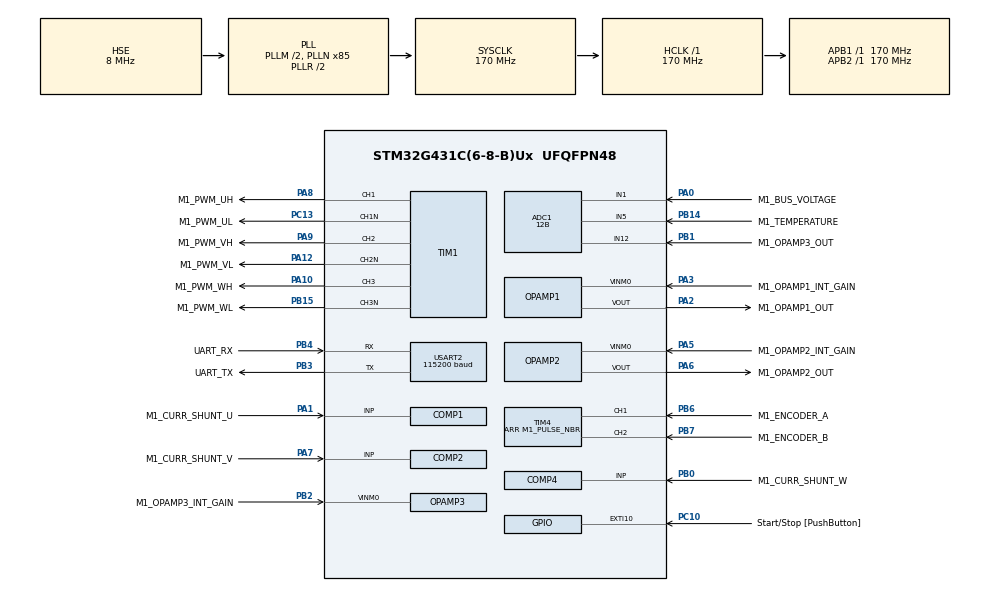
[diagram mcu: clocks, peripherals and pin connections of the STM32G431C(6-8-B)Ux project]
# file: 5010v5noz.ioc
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ADC1.Channel-1\#ChannelRegularConversion=ADC_CHANNEL_1
ADC1.Channel-2\#ChannelRegularConversion=ADC_CHANNEL_5
ADC1.ClockPrescaler=ADC_CLOCK_ASYNC_DIV1
ADC1.ContinuousConvMode=DISABLE
ADC1.DMAContinuousRequests=DISABLE
ADC1.DataAlign=ADC_DATAALIGN_LEFT
ADC1.DiscontinuousConvMode=DISABLE
ADC1.EOCSelection=ADC_EOC_SINGLE_CONV
ADC1.EnableAnalogWatchDog1=false
ADC1.EnableAnalogWatchDog2=false
ADC1.EnableAnalogWatchDog3=false
ADC1.EnableInjectedConversion=ENABLE
ADC1.EnableRegularConversion=ENABLE
ADC1.ExternalTrigConv=ADC_SOFTWARE_START
ADC1.ExternalTrigConvEdge=ADC_EXTERNALTRIGCONVEDGE_NONE
ADC1.ExternalTrigInjecConv=ADC_EXTERNALTRIGINJEC_T1_CC4
ADC1.ExternalTrigInjecConvEdge=ADC_EXTERNALTRIGINJECCONV_EDGE_RISING
ADC1.InjNumberOfConversion=2
ADC1.InjectedChannel-1\#ChannelInjectedConversion=ADC_CHANNEL_3
ADC1.InjectedChannel-2\#ChannelInjectedConversion=ADC_CHANNEL_12
ADC1.InjectedConvMode=None
ADC1.InjectedOffset-1\#ChannelInjectedConversion=0
ADC1.InjectedOffset-2\#ChannelInjectedConversion=0
ADC1.InjectedOffsetNumber-1\#ChannelInjectedConversion=ADC_OFFSET_NONE
ADC1.InjectedOffsetNumber-2\#ChannelInjectedConversion=ADC_OFFSET_NONE
ADC1.InjectedRank-1\#ChannelInjectedConversion=1
ADC1.InjectedRank-2\#ChannelInjectedConversion=2
ADC1.InjectedSamplingTime-1\#ChannelInjectedConversion=ADC_SAMPLETIME_6CYCLES_5
ADC1.InjectedSamplingTime-2\#ChannelInjectedConversion=ADC_SAMPLETIME_6CYCLES_5
ADC1.LowPowerAutoWait=DISABLE
ADC1.NbrOfConversion=2
ADC1.NbrOfConversionFlag=1
ADC1.Offset-1\#ChannelRegularConversion=0
ADC1.Offset-2\#ChannelRegularConversion=0
ADC1.OffsetNumber-1\#ChannelRegularConversion=ADC_OFFSET_NONE
ADC1.OffsetNumber-2\#ChannelRegularConversion=ADC_OFFSET_NONE
ADC1.Overrun=ADC_OVR_DATA_PRESERVED
ADC1.Rank-1\#ChannelRegularConversion=1
ADC1.Rank-2\#ChannelRegularConversion=2
ADC1.Resolution=ADC_RESOLUTION_12B
ADC1.SamplingTime-1\#ChannelRegularConversion=ADC_SAMPLETIME_47CYCLES_5
ADC1.SamplingTime-2\#ChannelRegularConversion=ADC_SAMPLETIME_47CYCLES_5
ADC1.ScanConvMode=ADC_SCAN_ENABLE
ADC1.master=1
ADC2.ClockPrescaler=ADC_CLOCK_ASYNC_DIV1
ADC2.ContinuousConvMode=DISABLE
ADC2.DMAContinuousRequests=DISABLE
ADC2.DataAlign=ADC_DATAALIGN_LEFT
ADC2.DiscontinuousConvMode=DISABLE
ADC2.EOCSelection=ADC_EOC_SINGLE_CONV
ADC2.EnableAnalogWatchDog1=false
ADC2.EnableAnalogWatchDog2=false
ADC2.EnableAnalogWatchDog3=false
ADC2.EnableInjectedConversion=ENABLE
ADC2.EnableRegularConversion=DISABLE
ADC2.ExternalTrigInjecConv=ADC_EXTERNALTRIGINJEC_T1_CC4
ADC2.ExternalTrigInjecConvEdge=ADC_EXTERNALTRIGINJECCONV_EDGE_RISING
ADC2.InjNumberOfConversion=2
ADC2.InjectedChannel-1\#ChannelInjectedConversion=ADC_CHANNEL_VOPAMP3_ADC2
ADC2.InjectedChannel-2\#ChannelInjectedConversion=ADC_CHANNEL_3
ADC2.InjectedConvMode=None
ADC2.InjectedOffset-1\#ChannelInjectedConversion=0
ADC2.InjectedOffset-2\#ChannelInjectedConversion=0
ADC2.InjectedOffsetNumber-1\#ChannelInjectedConversion=ADC_OFFSET_NONE
ADC2.InjectedOffsetNumber-2\#ChannelInjectedConversion=ADC_OFFSET_NONE
ADC2.InjectedRank-1\#ChannelInjectedConversion=1
ADC2.InjectedRank-2\#ChannelInjectedConversion=2
ADC2.InjectedSamplingTime-1\#ChannelInjectedConversion=ADC_SAMPLETIME_6CYCLES_5
ADC2.InjectedSamplingTime-2\#ChannelInjectedConversion=ADC_SAMPLETIME_6CYCLES_5
ADC2.LowPowerAutoWait=DISABLE
ADC2.Overrun=ADC_OVR_DATA_PRESERVED
ADC2.Resolution=ADC_RESOLUTION_12B
ADC2.ScanConvMode=ADC_SCAN_ENABLE
ADC2.master=1
DAC3.DAC_Channel-DAC_OUT2_Int=DAC_CHANNEL_2
Dma.Request0=USART2_RX
Dma.Request1=USART2_TX
Dma.USART2_RX.0.Direction=DMA_PERIPH_TO_MEMORY
Dma.USART2_RX.0.EventEnable=DISABLE
Dma.USART2_RX.0.Instance=DMA1_Channel1
Dma.USART2_RX.0.MemDataAlignment=DMA_MDATAALIGN_BYTE
Dma.USART2_RX.0.MemInc=DMA_MINC_ENABLE
Dma.USART2_RX.0.Mode=DMA_NORMAL
Dma.USART2_RX.0.PeriphDataAlignment=DMA_PDATAALIGN_BYTE
Dma.USART2_RX.0.PeriphInc=DMA_PINC_DISABLE
Dma.USART2_RX.0.Polarity=HAL_DMAMUX_REQ_GEN_RISING
Dma.USART2_RX.0.Priority=DMA_PRIORITY_LOW
Dma.USART2_RX.0.RequestNumber=1
Dma.USART2_RX.0.SignalID=NONE
Dma.USART2_RX.0.SyncEnable=DISABLE
Dma.USART2_RX.0.SyncPolarity=HAL_DMAMUX_SYNC_NO_EVENT
Dma.USART2_RX.0.SyncRequestNumber=1
Dma.USART2_RX.0.SyncSignalID=NONE
Dma.USART2_TX.1.Direction=DMA_MEMORY_TO_PERIPH
Dma.USART2_TX.1.EventEnable=DISABLE
Dma.USART2_TX.1.Instance=DMA1_Channel2
Dma.USART2_TX.1.MemDataAlignment=DMA_MDATAALIGN_BYTE
Dma.USART2_TX.1.MemInc=DMA_MINC_ENABLE
Dma.USART2_TX.1.Mode=DMA_NORMAL
Dma.USART2_TX.1.PeriphDataAlignment=DMA_PDATAALIGN_BYTE
Dma.USART2_TX.1.PeriphInc=DMA_PINC_DISABLE
Dma.USART2_TX.1.Polarity=HAL_DMAMUX_REQ_GEN_RISING
Dma.USART2_TX.1.Priority=DMA_PRIORITY_LOW
Dma.USART2_TX.1.RequestNumber=1
Dma.USART2_TX.1.SignalID=NONE
Dma.USART2_TX.1.SyncEnable=DISABLE
Dma.USART2_TX.1.SyncPolarity=HAL_DMAMUX_SYNC_NO_EVENT
Dma.USART2_TX.1.SyncRequestNumber=1
Dma.USART2_TX.1.SyncSignalID=NONE
ExtraMW=MotorControl
ExtraMW.MotorControl.Config=MotorControl
ExtraMW.MotorControl.Mode=MotorControl
ExtraMW.MotorControl.Root=MCSDK_v6.3.2-Full/MotorControl
ExtraMW.MotorControl.Template=templates
Mcu.Family=STM32G4
Mcu.Name=STM32G431C(6-8-B)Ux
Mcu.Package=UFQFPN48
MotorControl.ADC_1_PERIPH=ADC1
MotorControl.ADC_2_PERIPH=ADC2
MotorControl.ADC_AHBPERIPH=RCC_AHBPeriph_ADC12
MotorControl.ADC_CLOCK_WB_DIV=1
MotorControl.ADC_PERIPH=ADC1
MotorControl.ADC_REFERENCE_VOLTAGE=3.3
MotorControl.BOARD=B-G431B-ESC1
MotorControl.BUS_VOLTAGE_READING=true
MotorControl.CCMRAM_ENABLED=false
MotorControl.CLOCK_FREQUENCY=CPU_CLK_170_MHZ
MotorControl.CLOCK_SOURCE=EXTERNAL
MotorControl.CPU_CLK_170_MHZ=true
MotorControl.CTLBOARD_NAME=B-G431B-ESC1
MotorControl.CUBE_MX_VER=6.10.0
MotorControl.CURRENT_READING_TOPOLOGY=THREE_SHUNT_INDEPENDENT_RESOURCES
MotorControl.CURR_SAMPLING_TIME=6
MotorControl.DBG_MCU_LOAD_MEASURE=false
MotorControl.DEBUG_DAC_FUNCTIONALITY_EN=false
MotorControl.DRIVES_NUMBER_SELECTION=SINGLEDRIVE
MotorControl.DRIVE_NUMBER=1
MotorControl.DRIVE_TYPE=FOC
MotorControl.ENCODER=true
MotorControl.ENCODER_AVAILABLE=true
MotorControl.ENCODER_PPR=1024
MotorControl.ENC_A_GPIO_PIN=LL_GPIO_PIN_6
MotorControl.ENC_A_GPIO_PORT=GPIOB
MotorControl.ENC_B_GPIO_PIN=LL_GPIO_PIN_7
MotorControl.ENC_B_GPIO_PORT=GPIOB
MotorControl.ENC_ICx_FILTER=119
MotorControl.ENC_INVERT_SPEED=true
MotorControl.ENC_TIMER_SELECTION=ENC_TIM4
MotorControl.ENC_USE_CH3=false
MotorControl.EXT_CLK_8_MHZ=true
MotorControl.EXT_CLOCK_FREQUENCY=EXT_CLK_8_MHZ
MotorControl.FEEDBACK_NET_FILTERING=false
MotorControl.FLASH_SIZE=128
MotorControl.HALL_SENSORS_AVAILABLE=false
MotorControl.HIGH_SIDE_IDLE_STATE=false
MotorControl.HWV_CS=ThreeShunt_RawCurrents_Differential_InternalGain
MotorControl.HWV_OCP=ThreeShunt_RawCurrents_Protection_IntRef
MotorControl.HWV_PWM=DrivingHighAndLowSides
MotorControl.HW_COMPLEMENTED_LOW_SIDE=false
MotorControl.HW_DEAD_TIME_NS=800
MotorControl.INVERTERBOARD=ESC_G4
MotorControl.IPs=CORDIC,SYS,NVIC,RCC,MotorControl,TIM1,COMP1,DAC3,COMP2,COMP4,OPAMP1,OPAMP2,OPAMP3,ADC1,ADC2,TIM4,USART2,DMA
MotorControl.LOW_MEMORY_FOOTPRINT_REG=false
MotorControl.LOW_SIDE_IDLE_STATE=false
MotorControl.LOW_SIDE_SIGNALS_ENABLING=LS_PWM_TIMER
MotorControl.M1_ALIGNMENT_ANGLE_DEG=90
MotorControl.M1_ALIGNMENT_DURATION=700
MotorControl.M1_AMPLIFICATION_GAIN=9.14
MotorControl.M1_ANGC={0,0,0,0,0,0,0,0}
MotorControl.M1_AUXILIARY_SPEED_SENSOR=NONE
MotorControl.M1_BOARD_MAX_CURRENT=10
MotorControl.M1_BUS_VOLTAGE_READING=true
MotorControl.M1_COMMUTATION_STEP_TIME_BUF_SIZE=12
MotorControl.M1_CONSTANT1_D=115690
MotorControl.M1_CONSTANT1_Q=115690
MotorControl.M1_CONSTANT2_QD=15377
MotorControl.M1_CS_ADC_NUM=2
MotorControl.M1_CS_ADC_PHASE_SHARED=W
MotorControl.M1_CS_ADC_U=ADC1
MotorControl.M1_CS_ADC_V=ADC2
MotorControl.M1_CS_CHANNEL_SHARED=VPOPAMP3
MotorControl.M1_CS_CHANNEL_U=3
MotorControl.M1_CS_CHANNEL_V=3
MotorControl.M1_CS_CHANNEL_W=12
MotorControl.M1_CS_OPAMP_DIRECT_LINK_TO_ADC=ADC2
MotorControl.M1_CS_OPAMP_DYNAMIC_OUTPUT_SWITCH=true
MotorControl.M1_CS_OPAMP_NUM=3
MotorControl.M1_CS_OPAMP_PHASE_SHARED=NONE
MotorControl.M1_CS_OPAMP_U=OPAMP1
MotorControl.M1_CS_OPAMP_V=OPAMP2
MotorControl.M1_CS_OPAMP_VPSEL_U=PA1
MotorControl.M1_CS_OPAMP_VPSEL_V=PA7
MotorControl.M1_CS_OPAMP_VPSEL_W=PB0
MotorControl.M1_CS_OPAMP_W=OPAMP3
MotorControl.M1_CURRENT_AMPLIFICATION_TOPO=INT_DIFFERENTIAL
MotorControl.M1_CURRENT_SENSING_TOPO=THREE_SHUNT
MotorControl.M1_CURR_SAMPLING_TIME=6
MotorControl.M1_DAC_CURRENT_THRESHOLD=4083
MotorControl.M1_DBG_OPEN_LOOP_ENABLE=false
MotorControl.M1_DC_CURRENT_RS_MEAS=10
MotorControl.M1_DEFAULT_CONTROL_MODE=STC_SPEED_MODE
MotorControl.M1_DEFAULT_FLUX_COMPONENT=0
MotorControl.M1_DEFAULT_TARGET_SPEED_RPM=1078
MotorControl.M1_DEFAULT_TORQUE_COMPONENT=0
MotorControl.M1_DISCONTINUOUS_PWM=false
MotorControl.M1_DP_TOPOLOGY=NONE
MotorControl.M1_DRIVE_TYPE=FOC
MotorControl.M1_ENCODER_PPR=1024
MotorControl.M1_ENC_AVERAGING_FIFO_DEPTH=16
MotorControl.M1_ENC_A_GPIO_PIN=LL_GPIO_PIN_6
MotorControl.M1_ENC_A_GPIO_PORT=GPIOB
MotorControl.M1_ENC_B_GPIO_PIN=LL_GPIO_PIN_7
MotorControl.M1_ENC_B_GPIO_PORT=GPIOB
MotorControl.M1_ENC_ICx_FILTER=119
MotorControl.M1_ENC_TIMER_IRQ=TIM4
MotorControl.M1_ENC_TIMER_SELECTION=ENC_TIM4
MotorControl.M1_ENC_USE_CH3=false
MotorControl.M1_FEED_FORWARD_CURRENT_REG_ENABLING=false
MotorControl.M1_FINAL_I_ALIGNMENT=10
MotorControl.M1_FLUX_WEAKENING_ENABLING=false
MotorControl.M1_FW_KIDIV=32768
MotorControl.M1_FW_KI_GAIN=5000
MotorControl.M1_FW_KPDIV=32768
MotorControl.M1_FW_KP_GAIN=3000
MotorControl.M1_FW_VOLTAGE_REF=985
MotorControl.M1_HALL_PHASE_SHIFT=300
MotorControl.M1_HALL_SENSORS_PLACEMENT=DEGREES_120
MotorControl.M1_HIGH_SIDE_IDLE_STATE=false
MotorControl.M1_HW_DEAD_TIME_NS=800
MotorControl.M1_ICL_ENABLED=false
MotorControl.M1_ID_DEMAG=-10
MotorControl.M1_INT_AMP_OPAMP1_PIN=[{'mode'\:'Standalone','name'\:'PA1','signal'\:'OPAMP1_VINP','label'\:'SHUNT_P_U'},{'mode'\:'PGA Connected-INVERTINGINPUT_IO0_BIAS','name'\:'PA3','signal'\:'OPAMP1_VINM0','label'\:'SHUNT_M_U'}]
MotorControl.M1_INT_AMP_OPAMP2_PIN=[{'mode'\:'Standalone','name'\:'PA7','signal'\:'OPAMP2_VINP','label'\:'SHUNT_P_V'},{'mode'\:'PGA Connected-INVERTINGINPUT_IO0_BIAS','name'\:'PA5','signal'\:'OPAMP2_VINM0','label'\:'SHUNT_M_V'}]
MotorControl.M1_INT_AMP_OPAMP3_PIN=[{'mode'\:'Standalone','name'\:'PB0','signal'\:'OPAMP3_VINP','label'\:'SHUNT_P_W'},{'mode'\:'PGA Connected-INVERTINGINPUT_IO0_BIAS','name'\:'PB2','signal'\:'OPAMP3_VINM0','label'\:'SHUNT_M_W'}]
MotorControl.M1_INT_AMP_OPAMPS=['OPAMP1','OPAMP2','OPAMP3']
MotorControl.M1_IQMAX=10
MotorControl.M1_LDLQ_RATIO=1.000
MotorControl.M1_LOW_SIDE_IDLE_STATE=false
MotorControl.M1_LOW_SIDE_SIGNALS_ENABLING=LS_PWM_TIMER
MotorControl.M1_LS=0.00004
MotorControl.M1_MAX_APPLICATION_SPEED=2994
MotorControl.M1_MAX_MODULATION_INDEX=100
MotorControl.M1_MIN_APPLICATION_SPEED=0
MotorControl.M1_MOTOR_MAX_SPEED_RPM=2994
MotorControl.M1_MOTOR_NAME=5100v4
MotorControl.M1_MOTOR_RATED_FLUX=0.01608925
MotorControl.M1_MOTOR_VOLTAGE_CONSTANT=2.0
MotorControl.M1_MTPA_ENABLING=false
MotorControl.M1_NOMINAL_BUS_VOLTAGE_V=12
MotorControl.M1_NOMINAL_CURRENT=10
MotorControl.M1_OCP_BKIN_FILTER=3
MotorControl.M1_OCP_BKIN_MODE=INT_MODE
MotorControl.M1_OCP_BKIN_POLARITY=EMSTOP_ACTIVE_HIGH
MotorControl.M1_OCP_COMP_SRC=DAC
MotorControl.M1_OCP_COMP_U=COMP1
MotorControl.M1_OCP_COMP_V=COMP2
MotorControl.M1_OCP_COMP_W=COMP4
MotorControl.M1_OCP_DAC_CHANNEL_U=OUT1
MotorControl.M1_OCP_DAC_CHANNEL_V=OUT2
MotorControl.M1_OCP_DAC_CHANNEL_W=OUT2
MotorControl.M1_OCP_DAC_U=DAC3
MotorControl.M1_OCP_DAC_V=DAC3
MotorControl.M1_OCP_DAC_W=DAC3
MotorControl.M1_OCP_DESTINATION=TIM_BKIN
MotorControl.M1_OCP_TOPOLOGY=EMBEDDED
MotorControl.M1_OFST={0,0,0,0,0,0,0,0}
MotorControl.M1_ON_OVER_VOLTAGE=TURN_OFF_PWM
MotorControl.M1_OVERMODULATION=false
MotorControl.M1_OVP_THRESHOLD_HIGH=14
MotorControl.M1_OV_TEMPERATURE_HYSTERESIS_C=10
MotorControl.M1_OV_TEMPERATURE_PROT_ENABLING=true
MotorControl.M1_OV_TEMPERATURE_THRESHOLD_C=70
MotorControl.M1_OV_VOLTAGE_PROT_ENABLING=true
MotorControl.M1_OV_VOLTAGE_THRESHOLD_V=14
MotorControl.M1_PID_FLUX_KD_DEFAULT=100
MotorControl.M1_PID_FLUX_KI_DEFAULT=3099
MotorControl.M1_PID_FLUX_KP_DEFAULT=2479
MotorControl.M1_PID_SPEED_KD_DEFAULT=0
MotorControl.M1_PID_SPEED_KI_DEFAULT=79
MotorControl.M1_PID_SPEED_KP_DEFAULT=3077
MotorControl.M1_PID_TORQUE_KD_DEFAULT=100
MotorControl.M1_PID_TORQUE_KI_DEFAULT=3099
MotorControl.M1_PID_TORQUE_KP_DEFAULT=2479
MotorControl.M1_POLE_PAIR_NUM=6
MotorControl.M1_POSITION_CTRL_ENABLING=true
MotorControl.M1_POSITION_CTRL_KDDIV=16
MotorControl.M1_POSITION_CTRL_KD_GAIN=1000
MotorControl.M1_POSITION_CTRL_KIDIV=32768
MotorControl.M1_POSITION_CTRL_KI_GAIN=1000
MotorControl.M1_POSITION_CTRL_KPDIV=1024
MotorControl.M1_POSITION_CTRL_KP_GAIN=10000
MotorControl.M1_POSITION_LOOP_FREQUENCY_HZ=1000
MotorControl.M1_POTENTIOMETER_ENABLE=false
MotorControl.M1_POWERBOARD_NAME=B-G431B-ESC1
MotorControl.M1_PWM_CHARGE_BOOT_CAP_DUTY_CYCLES=0.000
MotorControl.M1_PWM_CHARGE_BOOT_CAP_MS=10
MotorControl.M1_PWM_DRIVER_PN=L6387E
MotorControl.M1_PWM_FREQUENCY=16000
MotorControl.M1_PWM_TIMER_BRK_IRQ=TIM1_BRK_TIM15
MotorControl.M1_PWM_TIMER_SELECTION=PWM_TIM1
MotorControl.M1_PWM_TIMER_UP_IRQ=TIM1_UP_TIM16
MotorControl.M1_REGULATION_EXECUTION_RATE=1
MotorControl.M1_RS=0.1
MotorControl.M1_RSHUNT=0.003
MotorControl.M1_SEGDIV=0
MotorControl.M1_SHARED_SIGNAL_ENABLE=false
MotorControl.M1_SPD_DIFFERENTIAL_TERM_ENABLING=false
MotorControl.M1_SPEED_SENSOR=QUAD_ENCODER
MotorControl.M1_SP_KDDIV=16
MotorControl.M1_SP_KIDIV=16384
MotorControl.M1_SP_KPDIV=1024
MotorControl.M1_SS_MEAS_ERRORS_BEFORE_FAULTS=3
MotorControl.M1_SW_DEADTIME_NS=750
MotorControl.M1_T0_C=25
MotorControl.M1_TEMPERATURE_READING=true
MotorControl.M1_TEMP_ADC_SAMPLING_TIME=47
MotorControl.M1_TEMP_FDBK_ADC=ADC1
MotorControl.M1_TEMP_FDBK_CHANNEL=ADC_CHANNEL_5
MotorControl.M1_TF_KDDIV=8192
MotorControl.M1_TF_KIDIV=8192
MotorControl.M1_TF_KPDIV=1024
MotorControl.M1_TNOISE_NS=1000
MotorControl.M1_TRISE_NS=1000
MotorControl.M1_T_MAX=70
MotorControl.M1_UD_VOLTAGE_THRESHOLD_V=8
MotorControl.M1_USE_INTERNAL_OPAMP=true
MotorControl.M1_UV_VOLTAGE_PROT_ENABLING=true
MotorControl.M1_V0_V=1.4
MotorControl.M1_VBUS_ADC=ADC1
MotorControl.M1_VBUS_ADC_SAMPLING_TIME=47
MotorControl.M1_VBUS_CHANNEL=ADC_CHANNEL_1
MotorControl.M1_VBUS_PARTITIONING_FACTOR=0.09625565501973242
MotorControl.M1_dV_dT=0.019
MotorControl.MAX_READABLE_CURRENT=60.201
MotorControl.MCPA_OVER_UART_A_STREAM=10
MotorControl.MCP_ASPEP_OVER_UART=true
MotorControl.MCP_ASYNC_EN=true
MotorControl.MCP_ASYNC_OVER_ASPEP_EN=true
MotorControl.MCP_ASYNC_OVER_UART_A_EN=true
MotorControl.MCP_DMACH_RX_UART_A=1
MotorControl.MCP_DMACH_TX_UART_A=2
MotorControl.MCP_DMA_RX_UART_A=DMA1
MotorControl.MCP_DMA_TX_UART_A=DMA1
MotorControl.MCP_EN=true
MotorControl.MCP_IRQ_HANDLER_DMA_RX_UART_A=DMA1_Channel1_IRQHandler
MotorControl.MCP_IRQ_HANDLER_UART_A=USART2_IRQHandler
MotorControl.MCP_OVER_ASPEP_EN=true
MotorControl.MCP_OVER_STLNK_EN=false
MotorControl.MCP_OVER_UART_A_EN=true
MotorControl.MCP_OVER_UART_B_EN=false
MotorControl.MCP_RX_SYNC_PAYLOAD_MAX=256
MotorControl.MCP_TX_ASYNC_PAYLOAD_MAX_UART_A=2048
MotorControl.MCP_TX_SYNC_PAYLOAD_MAX=256
MotorControl.MCU=STM32G431CB
MotorControl.MCU_FAMILY=STM32G4
MotorControl.MCU_LINE=STM32G4x1
MotorControl.MCU_NAME=STM32G431C(6-8-B)Ux
MotorControl.MCU_PACKAGE=UFQFPN48
MotorControl.MCU_TYPE=STM32G431CB
MotorControl.MCU_USERNAME=STM32G431CBUx
MotorControl.MC_WORKBENCH_VERSION=6.3.2
MotorControl.MOTOR_PROFILER=false
MotorControl.MOTOR_TYPE=PMSM
MotorControl.OCPA_DAC_INTERNAL_PIN=true
MotorControl.OCPA_INVERTINGINPUT=COMPX_InvertingInput_DAC3
MotorControl.OCPA_INVERTINGINPUT_DAC_OUT=OUT1
MotorControl.OCPA_INVERTINGINPUT_GPIO_PIN=LL_GPIO_PIN_4
MotorControl.OCPA_INVERTINGINPUT_GPIO_PORT=GPIOA
MotorControl.OCPA_INVERTINGINPUT_MODE=INT_MODE
MotorControl.OCPA_NONINVERTINGINPUT=COMP1_NonInvertingInput_PA1
MotorControl.OCPA_NONINVERTINGINPUT_GPIO_PIN=LL_GPIO_PIN_1
MotorControl.OCPA_NONINVERTINGINPUT_GPIO_PORT=GPIOA
MotorControl.OCPA_OUTPUT=COMP_Output_TIM1BKIN2
MotorControl.OCPA_OUTPUTPOL=COMP_OutputPol_NonInverted
MotorControl.OCPA_OUTPUT_GPIO_PIN=LL_GPIO_PIN_4
MotorControl.OCPA_OUTPUT_GPIO_PORT=GPIOA
MotorControl.OCPA_OUTPUT_MODE=INT_MODE
MotorControl.OCPA_SELECTION=COMP1
MotorControl.OCPB_DAC_INTERNAL_PIN=true
MotorControl.OCPB_INVERTINGINPUT=COMPX_InvertingInput_DAC3
MotorControl.OCPB_INVERTINGINPUT_DAC_OUT=OUT2
MotorControl.OCPB_INVERTINGINPUT_GPIO_PIN=LL_GPIO_PIN_4
MotorControl.OCPB_INVERTINGINPUT_GPIO_PORT=GPIOA
MotorControl.OCPB_INVERTINGINPUT_MODE=INT_MODE
MotorControl.OCPB_NONINVERTINGINPUT=COMP2_NonInvertingInput_PA7
MotorControl.OCPB_NONINVERTINGINPUT_GPIO_PIN=LL_GPIO_PIN_7
MotorControl.OCPB_NONINVERTINGINPUT_GPIO_PORT=GPIOA
MotorControl.OCPB_OUTPUT=COMP_Output_TIM1BKIN2
MotorControl.OCPB_OUTPUTPOL=COMP_OutputPol_NonInverted
MotorControl.OCPB_OUTPUT_GPIO_PIN=LL_GPIO_PIN_4
MotorControl.OCPB_OUTPUT_GPIO_PORT=GPIOA
MotorControl.OCPB_OUTPUT_MODE=INT_MODE
MotorControl.OCPB_SELECTION=COMP2
MotorControl.OCPC_DAC_INTERNAL_PIN=true
MotorControl.OCPC_INVERTINGINPUT=COMPX_InvertingInput_DAC3
MotorControl.OCPC_INVERTINGINPUT_DAC_OUT=OUT2
MotorControl.OCPC_INVERTINGINPUT_GPIO_PIN=LL_GPIO_PIN_4
MotorControl.OCPC_INVERTINGINPUT_GPIO_PORT=GPIOA
MotorControl.OCPC_INVERTINGINPUT_MODE=INT_MODE
MotorControl.OCPC_NONINVERTINGINPUT=COMP4_NonInvertingInput_PB0
MotorControl.OCPC_NONINVERTINGINPUT_GPIO_PIN=LL_GPIO_PIN_0
MotorControl.OCPC_NONINVERTINGINPUT_GPIO_PORT=GPIOB
MotorControl.OCPC_OUTPUT=COMP_Output_TIM1BKIN2
MotorControl.OCPC_OUTPUTPOL=COMP_OutputPol_NonInverted
MotorControl.OCPC_OUTPUT_GPIO_PIN=LL_GPIO_PIN_4
MotorControl.OCPC_OUTPUT_GPIO_PORT=GPIOA
MotorControl.OCPC_OUTPUT_MODE=INT_MODE
MotorControl.OCPC_SELECTION=COMP4
MotorControl.OCP_FILTER=COMP_Mode_HighSpeed
MotorControl.OCP_INVERTINGINPUT=COMPX_InvertingInput_V_REF
MotorControl.OCP_INVERTINGINPUT_MODE=INT_MODE
MotorControl.OCP_SELECTION=COMP1
MotorControl.ON_OVER_VOLTAGE=TURN_OFF_PWM
MotorControl.OPAMP1_INVERTINGINPUT=OPAMP1_InvertingInput_PA3
MotorControl.OPAMP1_INVERTINGINPUT_GPIO_PIN=LL_GPIO_PIN_3
MotorControl.OPAMP1_INVERTINGINPUT_GPIO_PORT=GPIOA
MotorControl.OPAMP1_INVERTINGINPUT_MODE=EXT_MODE
MotorControl.OPAMP1_NONINVERTINGINPUT_PHA=OPAMP1_NonInvertingInput_PA1
MotorControl.OPAMP1_NONINVERTINGINPUT_PHA_GPIO_PIN=LL_GPIO_PIN_1
MotorControl.OPAMP1_NONINVERTINGINPUT_PHA_GPIO_PORT=GPIOA
MotorControl.OPAMP1_OUT_GPIO_PIN=LL_GPIO_PIN_2
MotorControl.OPAMP1_OUT_GPIO_PORT=GPIOA
MotorControl.OPAMP1_SELECTION=OPAMP1
MotorControl.OPAMP2_INVERTINGINPUT=OPAMP2_InvertingInput_PA5
MotorControl.OPAMP2_INVERTINGINPUT_GPIO_PIN=LL_GPIO_PIN_5
MotorControl.OPAMP2_INVERTINGINPUT_GPIO_PORT=GPIOA
MotorControl.OPAMP2_INVERTINGINPUT_MODE=EXT_MODE
MotorControl.OPAMP2_NONINVERTINGINPUT_PHB=OPAMP2_NonInvertingInput_PA7
MotorControl.OPAMP2_NONINVERTINGINPUT_PHB_GPIO_PIN=LL_GPIO_PIN_7
MotorControl.OPAMP2_NONINVERTINGINPUT_PHB_GPIO_PORT=GPIOA
MotorControl.OPAMP2_OUT_GPIO_PIN=LL_GPIO_PIN_6
MotorControl.OPAMP2_OUT_GPIO_PORT=GPIOA
MotorControl.OPAMP2_SELECTION=OPAMP2
MotorControl.OPAMP3_INVERTINGINPUT=OPAMP3_InvertingInput_PB2
MotorControl.OPAMP3_INVERTINGINPUT_GPIO_PIN=LL_GPIO_PIN_2
MotorControl.OPAMP3_INVERTINGINPUT_GPIO_PORT=GPIOB
MotorControl.OPAMP3_INVERTINGINPUT_MODE=EXT_MODE
MotorControl.OPAMP3_NONINVERTINGINPUT_PHC=OPAMP3_NonInvertingInput_PB0
MotorControl.OPAMP3_NONINVERTINGINPUT_PHC_GPIO_PIN=LL_GPIO_PIN_0
MotorControl.OPAMP3_NONINVERTINGINPUT_PHC_GPIO_PORT=GPIOB
MotorControl.OPAMP3_OUT_GPIO_PIN=LL_GPIO_PIN_1
MotorControl.OPAMP3_OUT_GPIO_PORT=GPIOB
MotorControl.OPAMP3_SELECTION=OPAMP3
MotorControl.OPAMP_PGAGAIN=OPAMP_OPAMP_PGAGain_16
MotorControl.OPAMP_TYPE_GAIN=INTERNAL
MotorControl.OV_TEMPERATURE_PROT_ENABLING=true
MotorControl.OV_VOLTAGE_PROT_ENABLING=true
MotorControl.PHASE_UH_GPIO_PIN=LL_GPIO_PIN_8
MotorControl.PHASE_UH_GPIO_PORT=GPIOA
MotorControl.PHASE_UH_POLARITY=H_ACTIVE_HIGH
MotorControl.PHASE_UL_GPIO_PIN=LL_GPIO_PIN_13
MotorControl.PHASE_UL_GPIO_PORT=GPIOC
MotorControl.PHASE_UL_POLARITY=L_ACTIVE_HIGH
MotorControl.PHASE_U_CURR_ADC=ADC1
MotorControl.PHASE_U_CURR_CHANNEL=ADC_CHANNEL_3
MotorControl.PHASE_U_GPIO_PIN=LL_GPIO_PIN_2
MotorControl.PHASE_U_GPIO_PORT=GPIOA
MotorControl.PHASE_U_PWM_CHANNEL=TIM_Channel_1
MotorControl.PHASE_VH_GPIO_PIN=LL_GPIO_PIN_9
MotorControl.PHASE_VH_GPIO_PORT=GPIOA
MotorControl.PHASE_VH_POLARITY=H_ACTIVE_HIGH
MotorControl.PHASE_VL_GPIO_PIN=LL_GPIO_PIN_12
MotorControl.PHASE_VL_GPIO_PORT=GPIOA
MotorControl.PHASE_VL_POLARITY=L_ACTIVE_HIGH
MotorControl.PHASE_V_CURR_ADC=ADC2
MotorControl.PHASE_V_CURR_CHANNEL=ADC_CHANNEL_3
MotorControl.PHASE_V_GPIO_PIN=LL_GPIO_PIN_6
MotorControl.PHASE_V_GPIO_PORT=GPIOA
MotorControl.PHASE_V_PWM_CHANNEL=TIM_Channel_2
MotorControl.PHASE_WH_GPIO_PIN=LL_GPIO_PIN_10
MotorControl.PHASE_WH_GPIO_PORT=GPIOA
MotorControl.PHASE_WH_POLARITY=H_ACTIVE_HIGH
MotorControl.PHASE_WL_GPIO_PIN=LL_GPIO_PIN_15
MotorControl.PHASE_WL_GPIO_PORT=GPIOB
MotorControl.PHASE_WL_POLARITY=L_ACTIVE_HIGH
MotorControl.PHASE_W_CURR_ADC=ADC1
MotorControl.PHASE_W_CURR_CHANNEL=ADC_CHANNEL_12
MotorControl.PHASE_W_GPIO_PIN=LL_GPIO_PIN_1
MotorControl.PHASE_W_GPIO_PORT=GPIOB
MotorControl.PHASE_W_PWM_CHANNEL=TIM_Channel_3
MotorControl.PHASE_W_S_CURR_ADC=ADC2
MotorControl.PHASE_W_S_CURR_CHANNEL=ADC_Channel_VOPAMP3
MotorControl.PHASE_W_S_GPIO_PIN=VIRTUAL_PIN
MotorControl.PHASE_W_S_GPIO_PORT=VIRTUAL_PORT
MotorControl.POTENTIOMETER_READING=false
MotorControl.PWM_FREQUENCY=16000
MotorControl.PWM_TIMER_SELECTION=PWM_TIM1
MotorControl.REGULATION_EXECUTION_RATE=1
MotorControl.RTOS=NONE
MotorControl.R_BRAKE_SWITCH_OFF_THRES_V=11
MotorControl.SINGLEDRIVE=true
MotorControl.SPD_DIFFERENTIAL_TERM_ENABLING=false
MotorControl.SPEED_SENSOR_SELECTION=ENCODER
MotorControl.START_STOP_BTN=true
MotorControl.START_STOP_GPIO_PIN=LL_GPIO_PIN_10
MotorControl.START_STOP_GPIO_PORT=GPIOC
MotorControl.START_STOP_POLARITY=DIN_ACTIVE_LOW
MotorControl.START_STOP_POLARITY_EDGE=GPIO_NOPULL
MotorControl.STM32G431CB=true
MotorControl.SW_DEADTIME_NS=750
MotorControl.TEMPERATURE_READING=true
MotorControl.TEMP_ADC_SAMPLING_TIME=47
MotorControl.TEMP_FDBK_ADC=ADC1
MotorControl.TEMP_FDBK_CHANNEL=ADC_CHANNEL_5
MotorControl.TEMP_FDBK_GPIO_PIN=LL_GPIO_PIN_14
MotorControl.TEMP_FDBK_GPIO_PORT=GPIOB
MotorControl.TFDIFFERENTIAL_TERM_ENABLING=false
MotorControl.THREE_SHUNT_INDEPENDENT_RESOURCES=true
MotorControl.TRISE_NS=1000
MotorControl.USART_RX_GPIO_PIN=LL_GPIO_PIN_4
MotorControl.USART_RX_GPIO_PORT=GPIOB
MotorControl.USART_SELECTION=USE_USART2
MotorControl.USART_SELECTION_A=USART2
MotorControl.USART_SPEED=115200
MotorControl.USART_TX_GPIO_PIN=LL_GPIO_PIN_3
MotorControl.USART_TX_GPIO_PORT=GPIOB
MotorControl.USE_3OPAMPS=true
MotorControl.USE_INTERNAL_OPAMP=true
MotorControl.UV_VOLTAGE_PROT_ENABLING=true
MotorControl.VBUS_ADC=ADC1
MotorControl.VBUS_ADC_SAMPLING_TIME=47
MotorControl.VBUS_CHANNEL=ADC_CHANNEL_1
MotorControl.VBUS_GPIO_PIN=LL_GPIO_PIN_0
MotorControl.VBUS_GPIO_PORT=GPIOA
MotorControl.WB_UI_CUTOFF_FREQUENCY=6000
MotorControl.WB_UI_ENCODER_HAS_INDEX_PIN=true
MotorControl.WB_UI_FLUX_TARGET=0
MotorControl.WB_UI_FRICTION=2.25
MotorControl.WB_UI_GAIN=9.136
MotorControl.WB_UI_GAINLIST=[{'factor'\:2,'gain'\:1.142,'pol'\:0.257125,'maxVRef'\:3.3},{'factor'\:4,'gain'\:2.284,'pol'\:0.51425,'maxVRef'\:3.3},{'factor'\:8,'gain'\:4.568,'pol'\:1.0285,'maxVRef'\:3.3},{'factor'\:16,'gain'\:9.136,'pol'\:2.057,'maxVRef'\:3.3},{'factor'\:32,'gain'\:18.272,'pol'\:4.114,'maxVRef'\:3.3},{'factor'\:64,'gain'\:36.544,'pol'\:8.228,'maxVRef'\:3.3}]
MotorControl.WB_UI_GON=0.571
MotorControl.WB_UI_GOP=16
MotorControl.WB_UI_INERTIA=1.41
MotorControl.WB_UI_MAGNETIC_STRUCTURE=SM-PMSM
MotorControl.WB_UI_MAX_CURRENT=10
MotorControl.WB_UI_MAX_NOMINAL_DC_VOLTAGE=12
MotorControl.WB_UI_MAX_PWMFREQUENCY=100000
MotorControl.WB_UI_MOTOR_DESCRIPTION=Profile4_3000rpm
MotorControl.WB_UI_OCP_THRESHOLD=45
MotorControl.WB_UI_PW_BOARD_MAX_RATED_CURRENT=40
MotorControl.WB_UI_PW_BOARD_MAX_VOLTAGE=28
MotorControl.WB_UI_PW_BOARD_MIN_VOLTAGE=8
MotorControl.WB_UI_VPOL=2.057
MotorControl.WB_UI_VPOL_K=0.1285625
MotorControl.WB_to_Mx_template_version=24-04-17
MotorControl.WB_to_Mx_version=6.2.3
NVIC.ADC1_2_IRQn=true\:2\:0\:true\:true\:false\:5\:true\:true\:true
NVIC.DMA1_Channel1_IRQn=true\:3\:0\:true\:true\:false\:2\:true\:true\:true
NVIC.EXTI15_10_IRQn=true\:3\:0\:false\:true\:false\:7\:true\:true\:true
NVIC.PriorityGroup=NVIC_PRIORITYGROUP_3
NVIC.TIM1_BRK_TIM15_IRQn=true\:4\:1\:true\:true\:false\:3\:true\:true\:true
NVIC.TIM1_UP_TIM16_IRQn=true\:0\:0\:false\:true\:false\:4\:true\:true\:true
NVIC.TIM4_IRQn=true\:3\:0\:false\:true\:false\:6\:true\:true\:true
NVIC.USART2_IRQn=true\:3\:1\:true\:true\:false\:1\:true\:true\:true
OPAMP1.PgaGain=OPAMP_PGA_GAIN_16_OR_MINUS_15
OPAMP1.SelfCalibration=Disable
OPAMP2.PgaGain=OPAMP_PGA_GAIN_16_OR_MINUS_15
OPAMP2.SelfCalibration=Disable
OPAMP3.PgaGain=OPAMP_PGA_GAIN_16_OR_MINUS_15
OPAMP3.SelfCalibration=Disable
PA0.GPIO_Label=M1_BUS_VOLTAGE
PA0.Mode=IN1-Single-Ended
PA0.Signal=ADC1_IN1
PA1.GPIO_Label=M1_CURR_SHUNT_U
PA1.Signal=SharedAnalog_PA1
PA10.GPIO_Label=M1_PWM_WH
PA10.GPIO_PuPd=GPIO_PULLDOWN
PA10.GPIO_Speed=GPIO_SPEED_FREQ_HIGH
PA10.Signal=S_TIM1_CH3
PA12.GPIO_Label=M1_PWM_VL
PA12.GPIO_PuPd=GPIO_PULLDOWN
PA12.GPIO_Speed=GPIO_SPEED_FREQ_HIGH
PA12.Mode=PWM Generation2 CH2 CH2N
PA12.Signal=TIM1_CH2N
PA13.GPIO_Label=TMS
PA13.Mode=Serial_Wire
PA13.Signal=SYS_JTMS-SWDIO
PA14.GPIO_Label=TCK
PA14.Mode=Serial_Wire
PA14.Signal=SYS_JTCK-SWCLK
PA2.GPIO_Label=M1_OPAMP1_OUT
PA2.Signal=SharedAnalog_PA2
PA3.GPIO_Label=M1_OPAMP1_INT_GAIN
PA3.Mode=PGA Connected-INVERTINGINPUT_IO0_BIAS
PA3.Signal=OPAMP1_VINM0
PA5.GPIO_Label=M1_OPAMP2_INT_GAIN
PA5.Mode=PGA Connected-INVERTINGINPUT_IO0_BIAS
PA5.Signal=OPAMP2_VINM0
PA6.GPIO_Label=M1_OPAMP2_OUT
PA6.Signal=SharedAnalog_PA6
PA7.GPIO_Label=M1_CURR_SHUNT_V
PA7.Signal=SharedAnalog_PA7
PA8.GPIO_Label=M1_PWM_UH
PA8.GPIO_PuPd=GPIO_PULLDOWN
PA8.GPIO_Speed=GPIO_SPEED_FREQ_HIGH
PA8.Signal=S_TIM1_CH1
PA9.GPIO_Label=M1_PWM_VH
PA9.GPIO_PuPd=GPIO_PULLDOWN
PA9.GPIO_Speed=GPIO_SPEED_FREQ_HIGH
PA9.Signal=S_TIM1_CH2
PB0.GPIO_Label=M1_CURR_SHUNT_W
PB0.Signal=SharedAnalog_PB0
PB1.GPIO_Label=M1_OPAMP3_OUT
PB1.Signal=SharedAnalog_PB1
PB14.GPIO_Label=M1_TEMPERATURE
PB14.Mode=IN5-Single-Ended
PB14.Signal=ADC1_IN5
PB15.GPIO_Label=M1_PWM_WL
PB15.GPIO_PuPd=GPIO_PULLDOWN
PB15.GPIO_Speed=GPIO_SPEED_FREQ_HIGH
PB15.Mode=PWM Generation3 CH3 CH3N
PB15.Signal=TIM1_CH3N
PB2.GPIO_Label=M1_OPAMP3_INT_GAIN
PB2.Mode=PGA Internally connected_IO0_BIAS
PB2.Signal=OPAMP3_VINM0
PB3.GPIO_Label=UART_TX
PB3.GPIO_Mode=GPIO_MODE_AF_PP
PB3.GPIO_PuPd=GPIO_NOPULL
PB3.GPIO_Speed=GPIO_SPEED_FREQ_LOW
PB3.Mode=Asynchronous
PB3.Signal=USART2_TX
PB4.GPIO_Label=UART_RX
PB4.GPIO_Mode=GPIO_MODE_AF_PP
PB4.GPIO_PuPd=GPIO_NOPULL
PB4.GPIO_Speed=GPIO_SPEED_FREQ_LOW
PB4.Mode=Asynchronous
PB4.Signal=USART2_RX
PB6.GPIO_Label=M1_ENCODER_A
PB6.Signal=S_TIM4_CH1
PB7.GPIO_Label=M1_ENCODER_B
PB7.Signal=S_TIM4_CH2
PC10.GPIO_Label=Start/Stop [PushButton]
PC10.GPIO_ModeDefaultEXTI=GPIO_MODE_IT_FALLING
PC10.GPIO_PuPd=GPIO_NOPULL
PC10.Signal=GPXTI10
PC13.GPIO_Label=M1_PWM_UL
PC13.GPIO_PuPd=GPIO_PULLDOWN
PC13.GPIO_Speed=GPIO_SPEED_FREQ_HIGH
PC13.Mode=PWM Generation1 CH1 CH1N
PC13.Signal=TIM1_CH1N
PF0-OSC_IN.Mode=HSE-External-Oscillator
PF0-OSC_IN.Signal=RCC_OSC_IN
PF1-OSC_OUT.Mode=HSE-External-Oscillator
PF1-OSC_OUT.Signal=RCC_OSC_OUT
ProjectManager.HeapSize=0x200
ProjectManager.StackSize=0x400
ProjectManager.TargetToolchain=STM32CubeIDE
RCC.ADC12CLockSelection=RCC_ADC12CLKSOURCE_PLL
RCC.ADC12Freq_Value=42500000
RCC.AHBFreq_Value=170000000
RCC.APB1Freq_Value=170000000
RCC.APB1TimFreq_Value=170000000
RCC.APB2Freq_Value=170000000
RCC.APB2TimFreq_Value=170000000
RCC.CK48CLockSelection=RCC_USBCLKSOURCE_PLL
RCC.CortexFreq_Value=170000000
RCC.EXTERNAL_CLOCK_VALUE=12288000
RCC.EnbaleCSS=true
RCC.HCLKFreq_Value=170000000
RCC.HSE_VALUE=8000000
RCC.HSI48_VALUE=48000000
RCC.HSI_VALUE=16000000
RCC.LSE_VALUE=32768
RCC.PLLM=RCC_PLLM_DIV2
RCC.PLLN=85
RCC.PLLP=RCC_PLLP_DIV8
RCC.PLLSourceVirtual=RCC_PLLSOURCE_HSE
RCC.PREFETCH_ENABLE=1
RCC.SYSCLKFreq_VALUE=170000000
RCC.SYSCLKSource=RCC_SYSCLKSOURCE_PLLCLK
RCC.USBFreq_Value=170000000
RCC.VCOOutputFreq_Value=340000000
SH.S_TIM1_CH1.0=TIM1_CH1,PWM Generation1 CH1 CH1N
SH.S_TIM1_CH2.0=TIM1_CH2,PWM Generation2 CH2 CH2N
SH.S_TIM1_CH3.0=TIM1_CH3,PWM Generation3 CH3 CH3N
SH.S_TIM4_CH1.0=TIM4_CH1,Encoder_Interface
SH.S_TIM4_CH2.0=TIM4_CH2,Encoder_Interface
SH.SharedAnalog_PA1.0=COMP1_INP,INP
SH.SharedAnalog_PA1.1=OPAMP1_VINP,PGA Connected-INVERTINGINPUT_IO0_BIAS
SH.SharedAnalog_PA2.0=OPAMP1_VOUT,PGA Connected-INVERTINGINPUT_IO0_BIAS
SH.SharedAnalog_PA2.1=ADC1_IN3,IN3-Single-Ended
SH.SharedAnalog_PA6.0=OPAMP2_VOUT,PGA Connected-INVERTINGINPUT_IO0_BIAS
SH.SharedAnalog_PA6.1=ADC2_IN3,IN3-Single-Ended
SH.SharedAnalog_PA7.0=COMP2_INP,INP
SH.SharedAnalog_PA7.1=OPAMP2_VINP,PGA Connected-INVERTINGINPUT_IO0_BIAS
SH.SharedAnalog_PB0.0=COMP4_INP,INP
SH.SharedAnalog_PB0.1=OPAMP3_VINP,PGA Internally connected_IO0_BIAS
SH.SharedAnalog_PB1.0=OPAMP3_VOUT
SH.SharedAnalog_PB1.1=ADC1_IN12,IN12-Single-Ended
TIM1.AutoReloadPreload=TIM_AUTORELOAD_PRELOAD_DISABLE
TIM1.AutomaticOutput=TIM_AUTOMATICOUTPUT_DISABLE
TIM1.Break2Filter=3
TIM1.Break2Polarity=TIM_BREAK2POLARITY_HIGH
TIM1.Break2State=TIM_BREAK2_DISABLE
TIM1.BreakFilter=3
TIM1.BreakPolarity=TIM_BREAKPOLARITY_HIGH
TIM1.BreakState=TIM_BREAK_ENABLE
TIM1.Channel=TIM_CHANNEL_4
TIM1.Channel-PWM\ Generation1\ CH1\ CH1N=TIM_CHANNEL_1
TIM1.Channel-PWM\ Generation2\ CH2\ CH2N=TIM_CHANNEL_2
TIM1.Channel-PWM\ Generation3\ CH3\ CH3N=TIM_CHANNEL_3
TIM1.Channel-PWM\ Generation4\ No\ Output=TIM_CHANNEL_4
TIM1.ClearInputSource=TIM_CLEARINPUTSOURCE_NONE
TIM1.ClockDivision=TIM_CLOCKDIVISION_DIV2
TIM1.CounterMode=TIM_COUNTERMODE_CENTERALIGNED1
TIM1.DeadTime=((DEAD_TIME_COUNTS) / 2)
TIM1.LockLevel=TIM_LOCKLEVEL_OFF
TIM1.OC1Preload_PWM=ENABLE
TIM1.OC2Preload_PWM=ENABLE
TIM1.OC3Preload_PWM=ENABLE
TIM1.OC4Preload_PWM=ENABLE
TIM1.OCFastMode_PWM=TIM_OCFAST_DISABLE
TIM1.OCIdleState_1=TIM_OCIDLESTATE_RESET
TIM1.OCIdleState_2=TIM_OCIDLESTATE_RESET
TIM1.OCIdleState_3=TIM_OCIDLESTATE_RESET
TIM1.OCIdleState_4=TIM_OCIDLESTATE_RESET
TIM1.OCMode_PWM-PWM\ Generation1\ CH1\ CH1N=TIM_OCMODE_PWM1
TIM1.OCMode_PWM-PWM\ Generation2\ CH2\ CH2N=TIM_OCMODE_PWM1
TIM1.OCMode_PWM-PWM\ Generation3\ CH3\ CH3N=TIM_OCMODE_PWM1
TIM1.OCMode_PWM-PWM\ Generation4\ No\ Output=TIM_OCMODE_PWM2
TIM1.OCNIdleState_1=TIM_OCNIDLESTATE_RESET
TIM1.OCNIdleState_2=TIM_OCNIDLESTATE_RESET
TIM1.OCNIdleState_3=TIM_OCNIDLESTATE_RESET
TIM1.OCNPolarity_1=TIM_OCNPOLARITY_HIGH
TIM1.OCNPolarity_2=TIM_OCNPOLARITY_HIGH
TIM1.OCNPolarity_3=TIM_OCNPOLARITY_HIGH
TIM1.OCPolarity_1=TIM_OCPOLARITY_HIGH
TIM1.OCPolarity_2=TIM_OCPOLARITY_HIGH
TIM1.OCPolarity_3=TIM_OCPOLARITY_HIGH
TIM1.OCPolarity_4=TIM_OCPOLARITY_HIGH
TIM1.OffStateIDLEMode=TIM_OSSI_ENABLE
TIM1.OffStateRunMode=TIM_OSSR_ENABLE
TIM1.PeriodNoDither=((PWM_PERIOD_CYCLES) / 2)
TIM1.Prescaler=((TIM_CLOCK_DIVIDER) - 1)
TIM1.PulseNoDither_1=((PWM_PERIOD_CYCLES) / 4)
TIM1.PulseNoDither_2=((PWM_PERIOD_CYCLES) / 4)
TIM1.PulseNoDither_3=((PWM_PERIOD_CYCLES) / 4)
TIM1.PulseNoDither_4=(((PWM_PERIOD_CYCLES) / 2) - (HTMIN))
TIM1.RepetitionCounter=(REP_COUNTER)
TIM1.SourceBRK2DigInput=TIM_BREAKINPUTSOURCE_DISABLE
TIM1.SourceBRKCOMP1=TIM_BREAKINPUTSOURCE_ENABLE
TIM1.SourceBRKCOMP1Polarity=TIM_BREAKINPUTSOURCE_POLARITY_HIGH
TIM1.SourceBRKCOMP2=TIM_BREAKINPUTSOURCE_ENABLE
TIM1.SourceBRKCOMP2Polarity=TIM_BREAKINPUTSOURCE_POLARITY_HIGH
TIM1.SourceBRKCOMP4=TIM_BREAKINPUTSOURCE_ENABLE
TIM1.SourceBRKCOMP4Polarity=TIM_BREAKINPUTSOURCE_POLARITY_HIGH
TIM1.SourceBRKDigInput=TIM_BREAKINPUTSOURCE_DISABLE
TIM1.TIM_MasterOutputTrigger=TIM_TRGO_OC4REF
TIM1.TIM_MasterOutputTrigger2=TIM_TRGO2_RESET
TIM1.TIM_MasterSlaveMode=TIM_MASTERSLAVEMODE_DISABLE
TIM1.TIM_SlaveMode=TIM_SLAVEMODE_TRIGGER
TIM4.EncoderMode=TIM_ENCODERMODE_TI12
TIM4.IC1Filter=M1_ENC_IC_FILTER
TIM4.IC1Polarity=TIM_ICPOLARITY_RISING
TIM4.IC2Filter=M1_ENC_IC_FILTER
TIM4.IC2Polarity=TIM_ICPOLARITY_FALLING
TIM4.PeriodNoDither=M1_PULSE_NBR
USART2.BaudRate=115200
USART2.VirtualMode-Asynchronous=VM_ASYNC
USART2.WordLength=WORDLENGTH_8B
VP_ADC2_OPAMP_INTERNAL3.Mode=IN-OPAMP3
VP_COMP1_VS_DAC3OUT1.Mode=INM_DAC3OUT1
VP_COMP2_VS_DAC3OUT2.Mode=INM_DAC3OUT2
VP_COMP4_VS_DAC3OUT2.Mode=INM_DAC3OUT2
VP_CORDIC_VS_CORDIC.Mode=CORDIC_Activate
VP_DAC3_VS_DACI1.Mode=DAC_OUT1_Int
VP_DAC3_VS_DACI2.Mode=DAC_OUT2_Int
VP_MotorControl_MC_ENABLED.Mode=Enabled
VP_SYS_VS_DBSignals.Mode=DisableDeadBatterySignals
VP_TIM1_VS_no_output4.Mode=PWM Generation4 No Output
board=custom

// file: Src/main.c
/* USER CODE BEGIN Header */
/**
  ******************************************************************************
  * @file           : main.c
  * @brief          : Main program body
  ******************************************************************************
  * @attention
  *
  * Copyright (c) 2026 STMicroelectronics.
  * All rights reserved.
  *
  * This software is licensed under terms that can be found in the LICENSE file
  * in the root directory of this software component.
  * If no LICENSE file comes with this software, it is provided AS-IS.
  *
  ******************************************************************************
  */
/* USER CODE END Header */
#include "main.h"
#include <stdio.h>
#include <string.h>
#include <stdio.h>
#include <string.h>

ADC_HandleTypeDef hadc1;
ADC_HandleTypeDef hadc2;

COMP_HandleTypeDef hcomp1;
COMP_HandleTypeDef hcomp2;
COMP_HandleTypeDef hcomp4;

CORDIC_HandleTypeDef hcordic;

DAC_HandleTypeDef hdac3;

OPAMP_HandleTypeDef hopamp1;
OPAMP_HandleTypeDef hopamp2;
OPAMP_HandleTypeDef hopamp3;

TIM_HandleTypeDef htim1;
TIM_HandleTypeDef htim4;

UART_HandleTypeDef huart2;
DMA_HandleTypeDef hdma_usart2_rx;
DMA_HandleTypeDef hdma_usart2_tx;

void SystemClock_Config(void);
static void MX_GPIO_Init(void);
static void MX_DMA_Init(void);
static void MX_ADC1_Init(void);
static void MX_ADC2_Init(void);
static void MX_COMP1_Init(void);
static void MX_COMP2_Init(void);
static void MX_COMP4_Init(void);
static void MX_CORDIC_Init(void);
static void MX_DAC3_Init(void);
static void MX_OPAMP1_Init(void);
static void MX_OPAMP2_Init(void);
static void MX_OPAMP3_Init(void);
static void MX_TIM1_Init(void);
static void MX_TIM4_Init(void);
static void MX_USART2_UART_Init(void);
static void MX_NVIC_Init(void);

int main(void)
{

  /* MCU Configuration--------------------------------------------------------*/

  /* Reset of all peripherals, Initializes the Flash interface and the Systick. */
  HAL_Init();

  /* Configure the system clock */
  SystemClock_Config();

  /* Initialize all configured peripherals */
  MX_GPIO_Init();
  MX_DMA_Init();
  MX_ADC1_Init();
  MX_ADC2_Init();
  MX_COMP1_Init();
  MX_COMP2_Init();
  MX_COMP4_Init();
  MX_CORDIC_Init();
  MX_DAC3_Init();
  MX_OPAMP1_Init();
  MX_OPAMP2_Init();
  MX_OPAMP3_Init();
  MX_TIM1_Init();
  MX_TIM4_Init();
  MX_USART2_UART_Init();
  MX_MotorControl_Init();

  /* Initialize interrupts */
  MX_NVIC_Init();
  /* USER CODE BEGIN 2 */
  char buffer[100];
  int alignment_count = 0;

  MC_StartMotor1();
  sprintf(buffer, "Motor started\r\n");
  HAL_UART_Transmit(&huart2, (uint8_t*)buffer, strlen(buffer), 100);

  HAL_Delay(500);

  sprintf(buffer, "Initial alignment status: %d\r\n", MC_GetAlignmentStatusMotor1());
  HAL_UART_Transmit(&huart2, (uint8_t*)buffer, strlen(buffer), 100);

  /* USER CODE END 2 */

  /* Infinite loop */
  /* USER CODE BEGIN WHILE */
  sprintf(buffer, "ALIGNMENT COMPLETE!\r\n");
   HAL_UART_Transmit(&huart2, (uint8_t*)buffer, strlen(buffer), 100);

   MC_ProgramPositionCommandMotor1(1.0, 0.1);  // <-- ONCE, before loop

   while (1)
   {
   /* USER CODE END WHILE */
   /* USER CODE BEGIN 3 */

     float motor_pos = MC_GetCurrentPosition1();
     float target_pos = MC_GetTargetPosition1();
     int16_t encoder_raw = MC_GetElAngledppMotor1();
     PosCtrlStatus_t pos_status = MC_GetControlPositionStatusMotor1();

     int pos_int = (int)(motor_pos * 10000);
     int cmd_int = (int)(target_pos * 10000);

     sprintf(buffer, "CMD: %d | POS: %d | ENC: %d | STAT: %d\r\n", cmd_int, pos_int, encoder_raw, pos_status);
     HAL_UART_Transmit(&huart2, (uint8_t*)buffer, strlen(buffer), 100);

     HAL_Delay(1000);

   }
   /* USER CODE END 3 */
}
void SystemClock_Config(void)
{
  RCC_OscInitTypeDef RCC_OscInitStruct = {0};
  RCC_ClkInitTypeDef RCC_ClkInitStruct = {0};

  /** Configure the main internal regulator output voltage
  */
  HAL_PWREx_ControlVoltageScaling(PWR_REGULATOR_VOLTAGE_SCALE1_BOOST);

  /** Initializes the RCC Oscillators according to the specified parameters
  * in the RCC_OscInitTypeDef structure.
  */
  RCC_OscInitStruct.OscillatorType = RCC_OSCILLATORTYPE_HSE;
  RCC_OscInitStruct.HSEState = RCC_HSE_ON;
  RCC_OscInitStruct.PLL.PLLState = RCC_PLL_ON;
  RCC_OscInitStruct.PLL.PLLSource = RCC_PLLSOURCE_HSE;
  RCC_OscInitStruct.PLL.PLLM = RCC_PLLM_DIV2;
  RCC_OscInitStruct.PLL.PLLN = 85;
  RCC_OscInitStruct.PLL.PLLP = RCC_PLLP_DIV8;
  RCC_OscInitStruct.PLL.PLLQ = RCC_PLLQ_DIV2;
  RCC_OscInitStruct.PLL.PLLR = RCC_PLLR_DIV2;
  if (HAL_RCC_OscConfig(&RCC_OscInitStruct) != HAL_OK)
  {
    Error_Handler();
  }

  /** Initializes the CPU, AHB and APB buses clocks
  */
  RCC_ClkInitStruct.ClockType = RCC_CLOCKTYPE_HCLK|RCC_CLOCKTYPE_SYSCLK
                              |RCC_CLOCKTYPE_PCLK1|RCC_CLOCKTYPE_PCLK2;
  RCC_ClkInitStruct.SYSCLKSource = RCC_SYSCLKSOURCE_PLLCLK;
  RCC_ClkInitStruct.AHBCLKDivider = RCC_SYSCLK_DIV1;
  RCC_ClkInitStruct.APB1CLKDivider = RCC_HCLK_DIV1;
  RCC_ClkInitStruct.APB2CLKDivider = RCC_HCLK_DIV1;

  if (HAL_RCC_ClockConfig(&RCC_ClkInitStruct, FLASH_LATENCY_4) != HAL_OK)
  {
    Error_Handler();
  }

  /** Enables the Clock Security System
  */
  HAL_RCC_EnableCSS();
}

/**
  * @brief NVIC Configuration.
  * @retval None
  */
static void MX_NVIC_Init(void)
{
  /* USART2_IRQn interrupt configuration */
  HAL_NVIC_SetPriority(USART2_IRQn, 3, 1);
  HAL_NVIC_EnableIRQ(USART2_IRQn);
  /* DMA1_Channel1_IRQn interrupt configuration */
  HAL_NVIC_SetPriority(DMA1_Channel1_IRQn, 3, 0);
  HAL_NVIC_EnableIRQ(DMA1_Channel1_IRQn);
  /* TIM1_BRK_TIM15_IRQn interrupt configuration */
  HAL_NVIC_SetPriority(TIM1_BRK_TIM15_IRQn, 4, 1);
  HAL_NVIC_EnableIRQ(TIM1_BRK_TIM15_IRQn);
  /* TIM1_UP_TIM16_IRQn interrupt configuration */
  HAL_NVIC_SetPriority(TIM1_UP_TIM16_IRQn, 0, 0);
  HAL_NVIC_EnableIRQ(TIM1_UP_TIM16_IRQn);
  /* ADC1_2_IRQn interrupt configuration */
  HAL_NVIC_SetPriority(ADC1_2_IRQn, 2, 0);
  HAL_NVIC_EnableIRQ(ADC1_2_IRQn);
  /* TIM4_IRQn interrupt configuration */
  HAL_NVIC_SetPriority(TIM4_IRQn, 3, 0);
  HAL_NVIC_EnableIRQ(TIM4_IRQn);
  /* EXTI15_10_IRQn interrupt configuration */
  HAL_NVIC_SetPriority(EXTI15_10_IRQn, 3, 0);
  HAL_NVIC_EnableIRQ(EXTI15_10_IRQn);
}

static void MX_ADC1_Init(void)
{

  ADC_MultiModeTypeDef multimode = {0};
  ADC_InjectionConfTypeDef sConfigInjected = {0};
  ADC_ChannelConfTypeDef sConfig = {0};

  /** Common config
  */
  hadc1.Instance = ADC1;
  hadc1.Init.ClockPrescaler = ADC_CLOCK_ASYNC_DIV1;
  hadc1.Init.Resolution = ADC_RESOLUTION_12B;
  hadc1.Init.DataAlign = ADC_DATAALIGN_LEFT;
  hadc1.Init.GainCompensation = 0;
  hadc1.Init.ScanConvMode = ADC_SCAN_ENABLE;
  hadc1.Init.EOCSelection = ADC_EOC_SINGLE_CONV;
  hadc1.Init.LowPowerAutoWait = DISABLE;
  hadc1.Init.ContinuousConvMode = DISABLE;
  hadc1.Init.NbrOfConversion = 2;
  hadc1.Init.DiscontinuousConvMode = DISABLE;
  hadc1.Init.ExternalTrigConv = ADC_SOFTWARE_START;
  hadc1.Init.ExternalTrigConvEdge = ADC_EXTERNALTRIGCONVEDGE_NONE;
  hadc1.Init.DMAContinuousRequests = DISABLE;
  hadc1.Init.Overrun = ADC_OVR_DATA_PRESERVED;
  hadc1.Init.OversamplingMode = DISABLE;
  if (HAL_ADC_Init(&hadc1) != HAL_OK)
  {
    Error_Handler();
  }

  /** Configure the ADC multi-mode
  */
  multimode.Mode = ADC_MODE_INDEPENDENT;
  if (HAL_ADCEx_MultiModeConfigChannel(&hadc1, &multimode) != HAL_OK)
  {
    Error_Handler();
  }

  /** Configure Injected Channel
  */
  sConfigInjected.InjectedChannel = ADC_CHANNEL_3;
  sConfigInjected.InjectedRank = ADC_INJECTED_RANK_1;
  sConfigInjected.InjectedSamplingTime = ADC_SAMPLETIME_6CYCLES_5;
  sConfigInjected.InjectedSingleDiff = ADC_SINGLE_ENDED;
  sConfigInjected.InjectedOffsetNumber = ADC_OFFSET_NONE;
  sConfigInjected.InjectedOffset = 0;
  sConfigInjected.InjectedNbrOfConversion = 2;
  sConfigInjected.InjectedDiscontinuousConvMode = DISABLE;
  sConfigInjected.AutoInjectedConv = DISABLE;
  sConfigInjected.QueueInjectedContext = DISABLE;
  sConfigInjected.ExternalTrigInjecConv = ADC_EXTERNALTRIGINJEC_T1_CC4;
  sConfigInjected.ExternalTrigInjecConvEdge = ADC_EXTERNALTRIGINJECCONV_EDGE_RISING;
  sConfigInjected.InjecOversamplingMode = DISABLE;
  if (HAL_ADCEx_InjectedConfigChannel(&hadc1, &sConfigInjected) != HAL_OK)
  {
    Error_Handler();
  }

  /** Configure Injected Channel
  */
  sConfigInjected.InjectedChannel = ADC_CHANNEL_12;
  sConfigInjected.InjectedRank = ADC_INJECTED_RANK_2;
  if (HAL_ADCEx_InjectedConfigChannel(&hadc1, &sConfigInjected) != HAL_OK)
  {
    Error_Handler();
  }

  /** Configure Regular Channel
  */
  sConfig.Channel = ADC_CHANNEL_1;
  sConfig.Rank = ADC_REGULAR_RANK_1;
  sConfig.SamplingTime = ADC_SAMPLETIME_47CYCLES_5;
  sConfig.SingleDiff = ADC_SINGLE_ENDED;
  sConfig.OffsetNumber = ADC_OFFSET_NONE;
  sConfig.Offset = 0;
  if (HAL_ADC_ConfigChannel(&hadc1, &sConfig) != HAL_OK)
  {
    Error_Handler();
  }

  /** Configure Regular Channel
  */
  sConfig.Channel = ADC_CHANNEL_5;
  sConfig.Rank = ADC_REGULAR_RANK_2;
  if (HAL_ADC_ConfigChannel(&hadc1, &sConfig) != HAL_OK)
  {
    Error_Handler();
  }

}

static void MX_ADC2_Init(void)
{

  ADC_InjectionConfTypeDef sConfigInjected = {0};

  /** Common config
  */
  hadc2.Instance = ADC2;
  hadc2.Init.ClockPrescaler = ADC_CLOCK_ASYNC_DIV1;
  hadc2.Init.Resolution = ADC_RESOLUTION_12B;
  hadc2.Init.DataAlign = ADC_DATAALIGN_LEFT;
  hadc2.Init.GainCompensation = 0;
  hadc2.Init.ScanConvMode = ADC_SCAN_ENABLE;
  hadc2.Init.EOCSelection = ADC_EOC_SINGLE_CONV;
  hadc2.Init.LowPowerAutoWait = DISABLE;
  hadc2.Init.ContinuousConvMode = DISABLE;
  hadc2.Init.NbrOfConversion = 1;
  hadc2.Init.DiscontinuousConvMode = DISABLE;
  hadc2.Init.DMAContinuousRequests = DISABLE;
  hadc2.Init.Overrun = ADC_OVR_DATA_PRESERVED;
  hadc2.Init.OversamplingMode = DISABLE;
  if (HAL_ADC_Init(&hadc2) != HAL_OK)
  {
    Error_Handler();
  }

  /** Configure Injected Channel
  */
  sConfigInjected.InjectedChannel = ADC_CHANNEL_VOPAMP3_ADC2;
  sConfigInjected.InjectedRank = ADC_INJECTED_RANK_1;
  sConfigInjected.InjectedSamplingTime = ADC_SAMPLETIME_6CYCLES_5;
  sConfigInjected.InjectedSingleDiff = ADC_SINGLE_ENDED;
  sConfigInjected.InjectedOffsetNumber = ADC_OFFSET_NONE;
  sConfigInjected.InjectedOffset = 0;
  sConfigInjected.InjectedNbrOfConversion = 2;
  sConfigInjected.InjectedDiscontinuousConvMode = DISABLE;
  sConfigInjected.AutoInjectedConv = DISABLE;
  sConfigInjected.QueueInjectedContext = DISABLE;
  sConfigInjected.ExternalTrigInjecConv = ADC_EXTERNALTRIGINJEC_T1_CC4;
  sConfigInjected.ExternalTrigInjecConvEdge = ADC_EXTERNALTRIGINJECCONV_EDGE_RISING;
  sConfigInjected.InjecOversamplingMode = DISABLE;
  if (HAL_ADCEx_InjectedConfigChannel(&hadc2, &sConfigInjected) != HAL_OK)
  {
    Error_Handler();
  }

  /** Configure Injected Channel
  */
  sConfigInjected.InjectedChannel = ADC_CHANNEL_3;
  sConfigInjected.InjectedRank = ADC_INJECTED_RANK_2;
  if (HAL_ADCEx_InjectedConfigChannel(&hadc2, &sConfigInjected) != HAL_OK)
  {
    Error_Handler();
  }

}

static void MX_COMP1_Init(void)
{

  hcomp1.Instance = COMP1;
  hcomp1.Init.InputPlus = COMP_INPUT_PLUS_IO1;
  hcomp1.Init.InputMinus = COMP_INPUT_MINUS_DAC3_CH1;
  hcomp1.Init.OutputPol = COMP_OUTPUTPOL_NONINVERTED;
  hcomp1.Init.Hysteresis = COMP_HYSTERESIS_NONE;
  hcomp1.Init.BlankingSrce = COMP_BLANKINGSRC_NONE;
  hcomp1.Init.TriggerMode = COMP_TRIGGERMODE_NONE;
  if (HAL_COMP_Init(&hcomp1) != HAL_OK)
  {
    Error_Handler();
  }

}

static void MX_COMP2_Init(void)
{

  hcomp2.Instance = COMP2;
  hcomp2.Init.InputPlus = COMP_INPUT_PLUS_IO1;
  hcomp2.Init.InputMinus = COMP_INPUT_MINUS_DAC3_CH2;
  hcomp2.Init.OutputPol = COMP_OUTPUTPOL_NONINVERTED;
  hcomp2.Init.Hysteresis = COMP_HYSTERESIS_NONE;
  hcomp2.Init.BlankingSrce = COMP_BLANKINGSRC_NONE;
  hcomp2.Init.TriggerMode = COMP_TRIGGERMODE_NONE;
  if (HAL_COMP_Init(&hcomp2) != HAL_OK)
  {
    Error_Handler();
  }

}

static void MX_COMP4_Init(void)
{

  hcomp4.Instance = COMP4;
  hcomp4.Init.InputPlus = COMP_INPUT_PLUS_IO1;
  hcomp4.Init.InputMinus = COMP_INPUT_MINUS_DAC3_CH2;
  hcomp4.Init.OutputPol = COMP_OUTPUTPOL_NONINVERTED;
  hcomp4.Init.Hysteresis = COMP_HYSTERESIS_NONE;
  hcomp4.Init.BlankingSrce = COMP_BLANKINGSRC_NONE;
  hcomp4.Init.TriggerMode = COMP_TRIGGERMODE_NONE;
  if (HAL_COMP_Init(&hcomp4) != HAL_OK)
  {
    Error_Handler();
  }

}

static void MX_CORDIC_Init(void)
{

  hcordic.Instance = CORDIC;
  if (HAL_CORDIC_Init(&hcordic) != HAL_OK)
  {
    Error_Handler();
  }

}

static void MX_DAC3_Init(void)
{

  DAC_ChannelConfTypeDef sConfig = {0};

  /** DAC Initialization
  */
  hdac3.Instance = DAC3;
  if (HAL_DAC_Init(&hdac3) != HAL_OK)
  {
    Error_Handler();
  }

  /** DAC channel OUT1 config
  */
  sConfig.DAC_HighFrequency = DAC_HIGH_FREQUENCY_INTERFACE_MODE_AUTOMATIC;
  sConfig.DAC_DMADoubleDataMode = DISABLE;
  sConfig.DAC_SignedFormat = DISABLE;
  sConfig.DAC_SampleAndHold = DAC_SAMPLEANDHOLD_DISABLE;
  sConfig.DAC_Trigger = DAC_TRIGGER_NONE;
  sConfig.DAC_Trigger2 = DAC_TRIGGER_NONE;
  sConfig.DAC_OutputBuffer = DAC_OUTPUTBUFFER_DISABLE;
  sConfig.DAC_ConnectOnChipPeripheral = DAC_CHIPCONNECT_INTERNAL;
  sConfig.DAC_UserTrimming = DAC_TRIMMING_FACTORY;
  if (HAL_DAC_ConfigChannel(&hdac3, &sConfig, DAC_CHANNEL_1) != HAL_OK)
  {
    Error_Handler();
  }

  /** DAC channel OUT2 config
  */
  if (HAL_DAC_ConfigChannel(&hdac3, &sConfig, DAC_CHANNEL_2) != HAL_OK)
  {
    Error_Handler();
  }

}

static void MX_OPAMP1_Init(void)
{

  hopamp1.Instance = OPAMP1;
  hopamp1.Init.PowerMode = OPAMP_POWERMODE_NORMAL;
  hopamp1.Init.Mode = OPAMP_PGA_MODE;
  hopamp1.Init.NonInvertingInput = OPAMP_NONINVERTINGINPUT_IO0;
  hopamp1.Init.InternalOutput = DISABLE;
  hopamp1.Init.TimerControlledMuxmode = OPAMP_TIMERCONTROLLEDMUXMODE_DISABLE;
  hopamp1.Init.PgaConnect = OPAMP_PGA_CONNECT_INVERTINGINPUT_IO0_BIAS;
  hopamp1.Init.PgaGain = OPAMP_PGA_GAIN_16_OR_MINUS_15;
  hopamp1.Init.UserTrimming = OPAMP_TRIMMING_FACTORY;
  if (HAL_OPAMP_Init(&hopamp1) != HAL_OK)
  {
    Error_Handler();
  }

}

static void MX_OPAMP2_Init(void)
{

  hopamp2.Instance = OPAMP2;
  hopamp2.Init.PowerMode = OPAMP_POWERMODE_NORMAL;
  hopamp2.Init.Mode = OPAMP_PGA_MODE;
  hopamp2.Init.NonInvertingInput = OPAMP_NONINVERTINGINPUT_IO0;
  hopamp2.Init.InternalOutput = DISABLE;
  hopamp2.Init.TimerControlledMuxmode = OPAMP_TIMERCONTROLLEDMUXMODE_DISABLE;
  hopamp2.Init.PgaConnect = OPAMP_PGA_CONNECT_INVERTINGINPUT_IO0_BIAS;
  hopamp2.Init.PgaGain = OPAMP_PGA_GAIN_16_OR_MINUS_15;
  hopamp2.Init.UserTrimming = OPAMP_TRIMMING_FACTORY;
  if (HAL_OPAMP_Init(&hopamp2) != HAL_OK)
  {
    Error_Handler();
  }

}

static void MX_OPAMP3_Init(void)
{

  hopamp3.Instance = OPAMP3;
  hopamp3.Init.PowerMode = OPAMP_POWERMODE_NORMAL;
  hopamp3.Init.Mode = OPAMP_PGA_MODE;
  hopamp3.Init.NonInvertingInput = OPAMP_NONINVERTINGINPUT_IO0;
  hopamp3.Init.InternalOutput = ENABLE;
  hopamp3.Init.TimerControlledMuxmode = OPAMP_TIMERCONTROLLEDMUXMODE_DISABLE;
  hopamp3.Init.PgaConnect = OPAMP_PGA_CONNECT_INVERTINGINPUT_IO0_BIAS;
  hopamp3.Init.PgaGain = OPAMP_PGA_GAIN_16_OR_MINUS_15;
  hopamp3.Init.UserTrimming = OPAMP_TRIMMING_FACTORY;
  if (HAL_OPAMP_Init(&hopamp3) != HAL_OK)
  {
    Error_Handler();
  }

}

static void MX_TIM1_Init(void)
{

  TIM_MasterConfigTypeDef sMasterConfig = {0};
  TIMEx_BreakInputConfigTypeDef sBreakInputConfig = {0};
  TIM_OC_InitTypeDef sConfigOC = {0};
  TIM_BreakDeadTimeConfigTypeDef sBreakDeadTimeConfig = {0};

  htim1.Instance = TIM1;
  htim1.Init.Prescaler = ((TIM_CLOCK_DIVIDER) - 1);
  htim1.Init.CounterMode = TIM_COUNTERMODE_CENTERALIGNED1;
  htim1.Init.Period = ((PWM_PERIOD_CYCLES) / 2);
  htim1.Init.ClockDivision = TIM_CLOCKDIVISION_DIV2;
  htim1.Init.RepetitionCounter = (REP_COUNTER);
  htim1.Init.AutoReloadPreload = TIM_AUTORELOAD_PRELOAD_DISABLE;
  if (HAL_TIM_PWM_Init(&htim1) != HAL_OK)
  {
    Error_Handler();
  }
  sMasterConfig.MasterOutputTrigger = TIM_TRGO_OC4REF;
  sMasterConfig.MasterOutputTrigger2 = TIM_TRGO2_RESET;
  sMasterConfig.MasterSlaveMode = TIM_MASTERSLAVEMODE_DISABLE;
  if (HAL_TIMEx_MasterConfigSynchronization(&htim1, &sMasterConfig) != HAL_OK)
  {
    Error_Handler();
  }
  sBreakInputConfig.Source = TIM_BREAKINPUTSOURCE_COMP1;
  sBreakInputConfig.Enable = TIM_BREAKINPUTSOURCE_ENABLE;
  sBreakInputConfig.Polarity = TIM_BREAKINPUTSOURCE_POLARITY_HIGH;
  if (HAL_TIMEx_ConfigBreakInput(&htim1, TIM_BREAKINPUT_BRK, &sBreakInputConfig) != HAL_OK)
  {
    Error_Handler();
  }
  sBreakInputConfig.Source = TIM_BREAKINPUTSOURCE_COMP2;
  if (HAL_TIMEx_ConfigBreakInput(&htim1, TIM_BREAKINPUT_BRK, &sBreakInputConfig) != HAL_OK)
  {
    Error_Handler();
  }
  sBreakInputConfig.Source = TIM_BREAKINPUTSOURCE_COMP4;
  if (HAL_TIMEx_ConfigBreakInput(&htim1, TIM_BREAKINPUT_BRK, &sBreakInputConfig) != HAL_OK)
  {
    Error_Handler();
  }
  sConfigOC.OCMode = TIM_OCMODE_PWM1;
  sConfigOC.Pulse = ((PWM_PERIOD_CYCLES) / 4);
  sConfigOC.OCPolarity = TIM_OCPOLARITY_HIGH;
  sConfigOC.OCNPolarity = TIM_OCNPOLARITY_HIGH;
  sConfigOC.OCFastMode = TIM_OCFAST_DISABLE;
  sConfigOC.OCIdleState = TIM_OCIDLESTATE_RESET;
  sConfigOC.OCNIdleState = TIM_OCNIDLESTATE_RESET;
  if (HAL_TIM_PWM_ConfigChannel(&htim1, &sConfigOC, TIM_CHANNEL_1) != HAL_OK)
  {
    Error_Handler();
  }
  if (HAL_TIM_PWM_ConfigChannel(&htim1, &sConfigOC, TIM_CHANNEL_2) != HAL_OK)
  {
    Error_Handler();
  }
  if (HAL_TIM_PWM_ConfigChannel(&htim1, &sConfigOC, TIM_CHANNEL_3) != HAL_OK)
  {
    Error_Handler();
  }
  sConfigOC.OCMode = TIM_OCMODE_PWM2;
  sConfigOC.Pulse = (((PWM_PERIOD_CYCLES) / 2) - (HTMIN));
  if (HAL_TIM_PWM_ConfigChannel(&htim1, &sConfigOC, TIM_CHANNEL_4) != HAL_OK)
  {
    Error_Handler();
  }
  sBreakDeadTimeConfig.OffStateRunMode = TIM_OSSR_ENABLE;
  sBreakDeadTimeConfig.OffStateIDLEMode = TIM_OSSI_ENABLE;
  sBreakDeadTimeConfig.LockLevel = TIM_LOCKLEVEL_OFF;
  sBreakDeadTimeConfig.DeadTime = ((DEAD_TIME_COUNTS) / 2);
  sBreakDeadTimeConfig.BreakState = TIM_BREAK_ENABLE;
  sBreakDeadTimeConfig.BreakPolarity = TIM_BREAKPOLARITY_HIGH;
  sBreakDeadTimeConfig.BreakFilter = 3;
  sBreakDeadTimeConfig.BreakAFMode = TIM_BREAK_AFMODE_INPUT;
  sBreakDeadTimeConfig.Break2State = TIM_BREAK2_DISABLE;
  sBreakDeadTimeConfig.Break2Polarity = TIM_BREAK2POLARITY_HIGH;
  sBreakDeadTimeConfig.Break2Filter = 3;
  sBreakDeadTimeConfig.Break2AFMode = TIM_BREAK_AFMODE_INPUT;
  sBreakDeadTimeConfig.AutomaticOutput = TIM_AUTOMATICOUTPUT_DISABLE;
  if (HAL_TIMEx_ConfigBreakDeadTime(&htim1, &sBreakDeadTimeConfig) != HAL_OK)
  {
    Error_Handler();
  }
  HAL_TIM_MspPostInit(&htim1);

}

static void MX_TIM4_Init(void)
{

  TIM_Encoder_InitTypeDef sConfig = {0};
  TIM_MasterConfigTypeDef sMasterConfig = {0};

  htim4.Instance = TIM4;
  htim4.Init.Prescaler = 0;
  htim4.Init.CounterMode = TIM_COUNTERMODE_UP;
  htim4.Init.Period = M1_PULSE_NBR;
  htim4.Init.ClockDivision = TIM_CLOCKDIVISION_DIV1;
  htim4.Init.AutoReloadPreload = TIM_AUTORELOAD_PRELOAD_DISABLE;
  sConfig.EncoderMode = TIM_ENCODERMODE_TI12;
  sConfig.IC1Polarity = TIM_ICPOLARITY_RISING;
  sConfig.IC1Selection = TIM_ICSELECTION_DIRECTTI;
  sConfig.IC1Prescaler = TIM_ICPSC_DIV1;
  sConfig.IC1Filter = M1_ENC_IC_FILTER;
  sConfig.IC2Polarity = TIM_ICPOLARITY_FALLING;
  sConfig.IC2Selection = TIM_ICSELECTION_DIRECTTI;
  sConfig.IC2Prescaler = TIM_ICPSC_DIV1;
  sConfig.IC2Filter = M1_ENC_IC_FILTER;
  if (HAL_TIM_Encoder_Init(&htim4, &sConfig) != HAL_OK)
  {
    Error_Handler();
  }
  sMasterConfig.MasterOutputTrigger = TIM_TRGO_RESET;
  sMasterConfig.MasterSlaveMode = TIM_MASTERSLAVEMODE_DISABLE;
  if (HAL_TIMEx_MasterConfigSynchronization(&htim4, &sMasterConfig) != HAL_OK)
  {
    Error_Handler();
  }

}

static void MX_USART2_UART_Init(void)
{

  huart2.Instance = USART2;
  huart2.Init.BaudRate = 115200;
  huart2.Init.WordLength = UART_WORDLENGTH_8B;
  huart2.Init.StopBits = UART_STOPBITS_1;
  huart2.Init.Parity = UART_PARITY_NONE;
  huart2.Init.Mode = UART_MODE_TX_RX;
  huart2.Init.HwFlowCtl = UART_HWCONTROL_NONE;
  huart2.Init.OverSampling = UART_OVERSAMPLING_16;
  huart2.Init.OneBitSampling = UART_ONE_BIT_SAMPLE_DISABLE;
  huart2.Init.ClockPrescaler = UART_PRESCALER_DIV1;
  huart2.AdvancedInit.AdvFeatureInit = UART_ADVFEATURE_NO_INIT;
  if (HAL_UART_Init(&huart2) != HAL_OK)
  {
    Error_Handler();
  }
  if (HAL_UARTEx_SetTxFifoThreshold(&huart2, UART_TXFIFO_THRESHOLD_1_8) != HAL_OK)
  {
    Error_Handler();
  }
  if (HAL_UARTEx_SetRxFifoThreshold(&huart2, UART_RXFIFO_THRESHOLD_1_8) != HAL_OK)
  {
    Error_Handler();
  }
  if (HAL_UARTEx_DisableFifoMode(&huart2) != HAL_OK)
  {
    Error_Handler();
  }

}

static void MX_DMA_Init(void)
{

  /* DMA controller clock enable */
  __HAL_RCC_DMAMUX1_CLK_ENABLE();
  __HAL_RCC_DMA1_CLK_ENABLE();

}

static void MX_GPIO_Init(void)
{
  GPIO_InitTypeDef GPIO_InitStruct = {0};

  /* GPIO Ports Clock Enable */
  __HAL_RCC_GPIOC_CLK_ENABLE();
  __HAL_RCC_GPIOF_CLK_ENABLE();
  __HAL_RCC_GPIOA_CLK_ENABLE();
  __HAL_RCC_GPIOB_CLK_ENABLE();

  /*Configure GPIO pin : Start_Stop_Pin */
  GPIO_InitStruct.Pin = Start_Stop_Pin;
  GPIO_InitStruct.Mode = GPIO_MODE_IT_FALLING;
  GPIO_InitStruct.Pull = GPIO_NOPULL;
  HAL_GPIO_Init(Start_Stop_GPIO_Port, &GPIO_InitStruct);

}

void Error_Handler(void)
{
  __disable_irq();
  while (1)
  {
  }
}
